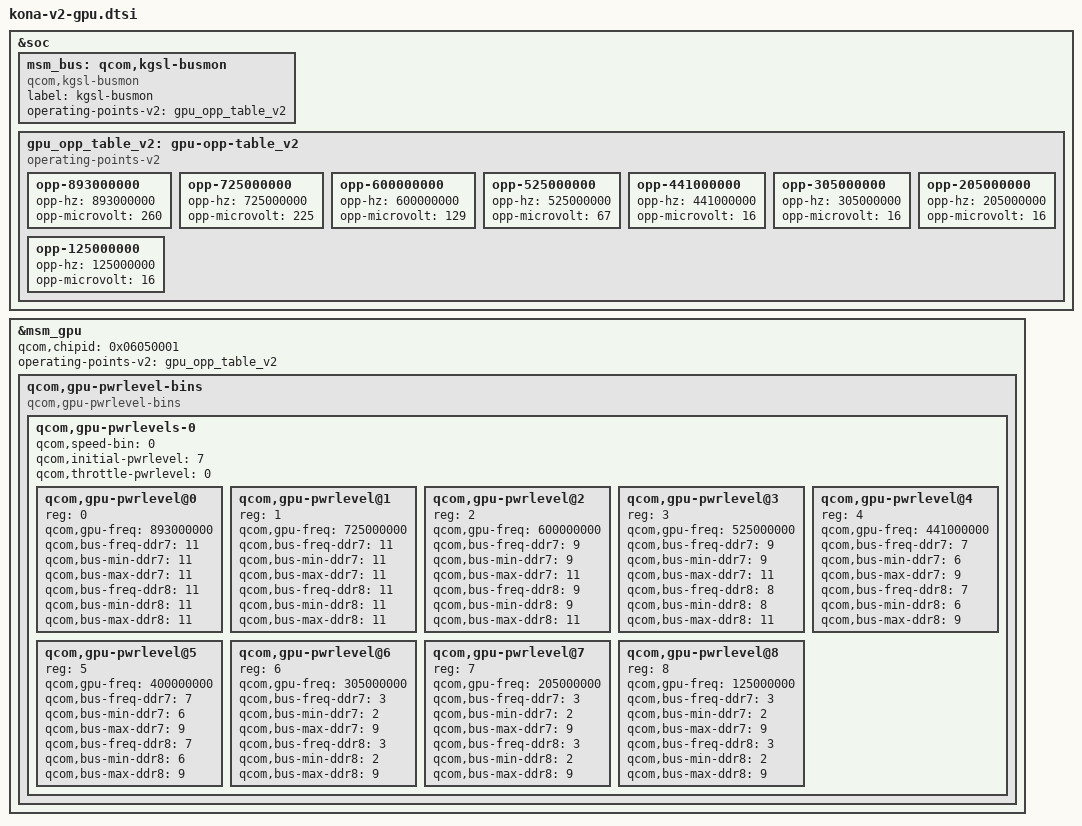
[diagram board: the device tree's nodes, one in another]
&soc {
    msm_bus: qcom,kgsl-busmon {
        label = "kgsl-busmon";
        compatible = "qcom,kgsl-busmon";
        operating-points-v2 = <&gpu_opp_table_v2>;
    };

    gpu_opp_table_v2: gpu-opp-table_v2 {
        compatible = "operating-points-v2";

        opp-893000000 { opp-hz = /bits/ 64 <893000000>; opp-microvolt = <260>; };
        opp-725000000 { opp-hz = /bits/ 64 <725000000>; opp-microvolt = <225>; };
        opp-600000000 { opp-hz = /bits/ 64 <600000000>; opp-microvolt = <129>; };
        opp-525000000 { opp-hz = /bits/ 64 <525000000>; opp-microvolt = <67>;  };
        opp-441000000 { opp-hz = /bits/ 64 <441000000>; opp-microvolt = <16>;  };
        opp-305000000 { opp-hz = /bits/ 64 <305000000>; opp-microvolt = <16>;  };
        opp-205000000 { opp-hz = /bits/ 64 <205000000>; opp-microvolt = <16>;  };
        opp-125000000 { opp-hz = /bits/ 64 <125000000>; opp-microvolt = <16>;  };
    };
};

&msm_gpu {
    qcom,chipid = <0x06050001>;
    operating-points-v2 = <&gpu_opp_table_v2>;

    /delete-property/qcom,initial-pwrlevel;
    /delete-node/qcom,gpu-pwrlevels;

    qcom,gpu-pwrlevel-bins {
        compatible="qcom,gpu-pwrlevel-bins";
        #address-cells = <1>;
        #size-cells = <0>;

        qcom,gpu-pwrlevels-0 {
            #address-cells = <1>;
            #size-cells = <0>;
            qcom,speed-bin = <0>;
            qcom,initial-pwrlevel = <7>; /* lowest bin = 125 MHz */
            qcom,throttle-pwrlevel = <0>;

            qcom,gpu-pwrlevel@0 { reg = <0>; qcom,gpu-freq = <893000000>;
                qcom,bus-freq-ddr7 = <11>; qcom,bus-min-ddr7 = <11>; qcom,bus-max-ddr7 = <11>;
                qcom,bus-freq-ddr8 = <11>; qcom,bus-min-ddr8 = <11>; qcom,bus-max-ddr8 = <11>; };

            qcom,gpu-pwrlevel@1 { reg = <1>; qcom,gpu-freq = <725000000>;
                qcom,bus-freq-ddr7 = <11>; qcom,bus-min-ddr7 = <11>; qcom,bus-max-ddr7 = <11>;
                qcom,bus-freq-ddr8 = <11>; qcom,bus-min-ddr8 = <11>; qcom,bus-max-ddr8 = <11>; };

            qcom,gpu-pwrlevel@2 { reg = <2>; qcom,gpu-freq = <600000000>;
                qcom,bus-freq-ddr7 = <9>; qcom,bus-min-ddr7 = <9>; qcom,bus-max-ddr7 = <11>;
                qcom,bus-freq-ddr8 = <9>; qcom,bus-min-ddr8 = <9>; qcom,bus-max-ddr8 = <11>; };

            qcom,gpu-pwrlevel@3 { reg = <3>; qcom,gpu-freq = <525000000>;
                qcom,bus-freq-ddr7 = <9>; qcom,bus-min-ddr7 = <9>; qcom,bus-max-ddr7 = <11>;
                qcom,bus-freq-ddr8 = <8>; qcom,bus-min-ddr8 = <8>; qcom,bus-max-ddr8 = <11>; };

            qcom,gpu-pwrlevel@4 { reg = <4>; qcom,gpu-freq = <441000000>;
                qcom,bus-freq-ddr7 = <7>; qcom,bus-min-ddr7 = <6>; qcom,bus-max-ddr7 = <9>;
                qcom,bus-freq-ddr8 = <7>; qcom,bus-min-ddr8 = <6>; qcom,bus-max-ddr8 = <9>; };

            qcom,gpu-pwrlevel@5 { reg = <5>; qcom,gpu-freq = <400000000>;
                qcom,bus-freq-ddr7 = <7>; qcom,bus-min-ddr7 = <6>; qcom,bus-max-ddr7 = <9>;
                qcom,bus-freq-ddr8 = <7>; qcom,bus-min-ddr8 = <6>; qcom,bus-max-ddr8 = <9>; };

            qcom,gpu-pwrlevel@6 { reg = <6>; qcom,gpu-freq = <305000000>;
                qcom,bus-freq-ddr7 = <3>; qcom,bus-min-ddr7 = <2>; qcom,bus-max-ddr7 = <9>;
                qcom,bus-freq-ddr8 = <3>; qcom,bus-min-ddr8 = <2>; qcom,bus-max-ddr8 = <9>; };

            qcom,gpu-pwrlevel@7 { reg = <7>; qcom,gpu-freq = <205000000>;
                qcom,bus-freq-ddr7 = <3>; qcom,bus-min-ddr7 = <2>; qcom,bus-max-ddr7 = <9>;
                qcom,bus-freq-ddr8 = <3>; qcom,bus-min-ddr8 = <2>; qcom,bus-max-ddr8 = <9>; };

            qcom,gpu-pwrlevel@8 { reg = <8>; qcom,gpu-freq = <125000000>;
                qcom,bus-freq-ddr7 = <3>; qcom,bus-min-ddr7 = <2>; qcom,bus-max-ddr7 = <9>;
                qcom,bus-freq-ddr8 = <3>; qcom,bus-min-ddr8 = <2>; qcom,bus-max-ddr8 = <9>; };
        };
    };
};
